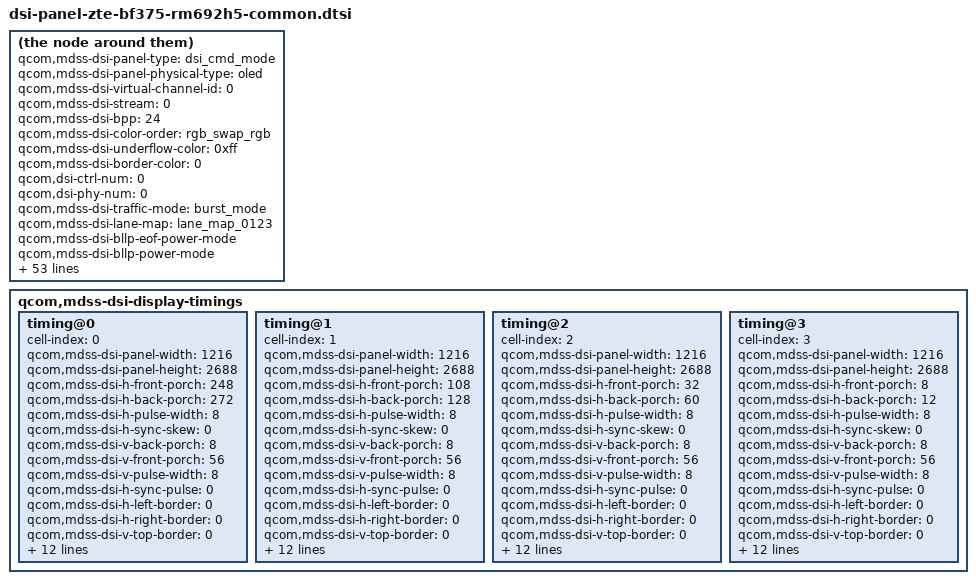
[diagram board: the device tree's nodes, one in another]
qcom,mdss-dsi-panel-type = "dsi_cmd_mode";
qcom,mdss-dsi-panel-physical-type = "oled";
qcom,mdss-dsi-virtual-channel-id = <0>;
qcom,mdss-dsi-stream = <0>;
qcom,mdss-dsi-bpp = <24>;
qcom,mdss-dsi-color-order = "rgb_swap_rgb";
qcom,mdss-dsi-underflow-color = <0xff>;
qcom,mdss-dsi-border-color = <0>;
qcom,dsi-ctrl-num = <0>;
qcom,dsi-phy-num = <0>;
qcom,mdss-dsi-traffic-mode = "burst_mode";
qcom,mdss-dsi-lane-map = "lane_map_0123";
qcom,mdss-dsi-bllp-eof-power-mode;
qcom,mdss-dsi-bllp-power-mode;
qcom,mdss-dsi-lane-0-state;
qcom,mdss-dsi-lane-1-state;
qcom,mdss-dsi-lane-2-state;
qcom,mdss-dsi-lane-3-state;
qcom,mdss-dsi-lp11-init;
qcom,mdss-dsi-tx-eot-append;
/* disp parameter */
qcom,mdss-dsi-dma-trigger = "trigger_sw";
qcom,mdss-dsi-mdp-trigger = "none";
qcom,mdss-dsi-reset-sequence = <1 10>, <0 10>, <1 40>;
qcom,mdss-dsi-te-pin-select = <1>;
qcom,mdss-dsi-te-dcs-command = <1>;
qcom,mdss-dsi-te-check-enable;
qcom,mdss-dsi-te-using-te-pin;
qcom,mdss-dsi-bl-min-level = <2>;
qcom,mdss-dsi-bl-max-level = <8190>; // 7030
qcom,mdss-dsi-panel-hdr-enabled;
qcom,mdss-dsi-panel-hdr-color-primaries = <14500 15500 34015
15980 13030 34670 6950 2565>;
qcom,mdss-dsi-panel-peak-brightness = <6680000>;
qcom,mdss-dsi-panel-blackness-level = <20>;
qcom,mdss-pan-physical-width-dimension = <72>;
qcom,mdss-pan-physical-height-dimension = <158>;
qcom,bl-dcs-cmd-state = "dsi_lp_mode";
qcom,bl-dsc-cmd-state = "dsi_lp_mode";
qcom,mdss-disable-cesta-hw-sleep;

/* feature */
zte,hbm_enabled;
zte,fps_enabled;
zte,aod_enabled;
zte,acl_enabled;
zte,color_space_enabled;
zte,bl_limit_enabled;
zte,te-high-width = <8500>;
zte,bl-normalmax-level = <7030>; // 7030

/* supply */
qcom,panel-supply-entries = <&dsi_panel_pwr_supply>;
qcom,mdss-dsi-bl-pmic-control-type = "bl_ctrl_dcs";
qcom,mdss-brightness-max-level = <8190>;
qcom,mdss-dsi-bl-inverted-dbv;
qcom,platform-reset-gpio = <&tlmm 98 0>;
qcom,ulps-enabled;
qcom,esd-check-enabled;
qcom,mdss-dsi-panel-status-check-mode = "reg_read";
qcom,mdss-dsi-panel-status-command = [
	06 01 00 01 05 00 01 0A
	06 01 00 01 05 00 01 FA
	06 01 00 01 05 00 01 0B];
qcom,mdss-dsi-panel-status-command-state = "dsi_lp_mode";
qcom,mdss-dsi-panel-status-value = <0x9c 0x01 0x00>;
qcom,mdss-dsi-panel-status-read-length = <1 1 1>;
qcom,dsi-select-clocks = "pll_byte_clk0", "pll_dsi_clk0";

/* qcom timing */
qcom,mdss-dsi-display-timings {
	timing@0 {
		cell-index = <0>;
		qcom,mdss-dsi-panel-width = <1216>;
		qcom,mdss-dsi-panel-height = <2688>;
		qcom,mdss-dsi-h-front-porch = <248>;
		qcom,mdss-dsi-h-back-porch = <272>;
		qcom,mdss-dsi-h-pulse-width = <8>;
		qcom,mdss-dsi-h-sync-skew = <0>;
		qcom,mdss-dsi-v-back-porch = <8>;
		qcom,mdss-dsi-v-front-porch = <56>;
		qcom,mdss-dsi-v-pulse-width = <8>;
		qcom,mdss-dsi-h-sync-pulse = <0>;
		qcom,mdss-dsi-h-left-border = <0>;
		qcom,mdss-dsi-h-right-border = <0>;
		qcom,mdss-dsi-v-top-border = <0>;
		qcom,mdss-dsi-v-bottom-border = <0>;
		qcom,mdss-dsi-panel-framerate = <60>;
		qcom,mdss-mdp-transfer-time-us = <6235>;
		/*qcom,mdss-dsi-panel-clockrate = <1060499680>;*/
		/*qcom,mdss-dsi-panel-clockrate = <1059430000>; 60HZ*/
		#include "dsi-panel-zte-bf375-rm692h5-6p8-common.dtsi"
		qcom,mdss-dsi-on-command = [
		/* ESD RECOVER */
		15 01 00 00 00 00 02 FE D4
		15 01 00 00 00 00 02 40 03
		15 01 00 00 00 00 02 FE FD
		15 01 00 00 00 00 02 80 06
		15 01 00 00 00 00 02 83 00
		15 01 00 00 00 00 02 EE 00
		15 01 00 00 00 00 02 EF 00
		15 01 00 00 00 00 02 FE D0
		15 01 00 00 00 00 02 7E 80
		15 01 00 00 00 00 02 FE B6
		15 01 00 00 00 00 02 01 74
		15 01 00 00 00 00 02 FE A1
		15 01 00 00 00 00 02 74 72
		15 01 00 00 00 00 02 C3 C3
		15 01 00 00 00 00 02 C4 FF
		15 01 00 00 00 00 02 C5 7F
		/*10bit 3.75 begin*/
		15 01 00 00 00 00 02 FE 00
		15 01 00 00 00 00 02 FA 01
		15 01 00 00 00 00 02 FE D2
		15 01 00 00 00 00 02 97 08
		15 01 00 00 00 00 02 36 11
		15 01 00 00 00 00 02 39 ab
		15 01 00 00 00 00 02 3A 30
		15 01 00 00 00 00 02 3B 80
		15 01 00 00 00 00 02 3D 0a
		15 01 00 00 00 00 02 3F 80
		15 01 00 00 00 00 02 40 04
		15 01 00 00 00 00 02 41 c0
		15 01 00 00 00 00 02 42 00
		15 01 00 00 00 00 02 43 10
		15 01 00 00 00 00 02 44 02
		15 01 00 00 00 00 02 45 60
		15 01 00 00 00 00 02 46 02
		15 01 00 00 00 00 02 47 60
		15 01 00 00 00 00 02 48 02
		15 01 00 00 00 00 02 49 00
		15 01 00 00 00 00 02 4A 02
		15 01 00 00 00 00 02 4B 31
		15 01 00 00 00 00 02 4D 20
		15 01 00 00 00 00 02 4E 01
		15 01 00 00 00 00 02 4F 68
		15 01 00 00 00 00 02 50 00
		15 01 00 00 00 00 02 51 08
		15 01 00 00 00 00 02 53 0c
		15 01 00 00 00 00 02 54 06
		15 01 00 00 00 00 02 55 67
		15 01 00 00 00 00 02 56 05
		15 01 00 00 00 00 02 58 ad
		15 01 00 00 00 00 02 59 18
		15 01 00 00 00 00 02 5A 00
		15 01 00 00 00 00 02 5B 11
		15 01 00 00 00 00 02 5C 00
		15 01 00 00 00 00 02 5D 07
		15 01 00 00 00 00 02 5E 10
		15 01 00 00 00 00 02 5F 20
		15 01 00 00 00 00 02 60 00
		15 01 00 00 00 00 02 61 06
		15 01 00 00 00 00 02 62 0f
		15 01 00 00 00 00 02 63 0f
		15 01 00 00 00 00 02 64 33
		15 01 00 00 00 00 02 65 0e
		15 01 00 00 00 00 02 66 1c
		15 01 00 00 00 00 02 67 2a
		15 01 00 00 00 00 02 68 38
		15 01 00 00 00 00 02 69 46
		15 01 00 00 00 00 02 6A 54
		15 01 00 00 00 00 02 6B 62
		15 01 00 00 00 00 02 6C 69
		15 01 00 00 00 00 02 6D 70
		15 01 00 00 00 00 02 6E 77
		15 01 00 00 00 00 02 6F 79
		15 01 00 00 00 00 02 70 7b
		15 01 00 00 00 00 02 71 7d
		15 01 00 00 00 00 02 72 7e
		15 01 00 00 00 00 02 73 02
		15 01 00 00 00 00 02 74 02
		15 01 00 00 00 00 02 75 22
		15 01 00 00 00 00 02 76 00
		15 01 00 00 00 00 02 77 2a
		15 01 00 00 00 00 02 78 40
		15 01 00 00 00 00 02 79 2a
		15 01 00 00 00 00 02 7A be
		15 01 00 00 00 00 02 7B 3a
		15 01 00 00 00 00 02 7C fc
		15 01 00 00 00 00 02 7D 3a
		15 01 00 00 00 00 02 7E fa
		15 01 00 00 00 00 02 7F 3a
		15 01 00 00 00 00 02 80 f8
		15 01 00 00 00 00 02 81 3b
		15 01 00 00 00 00 02 82 38
		15 01 00 00 00 00 02 83 3b
		15 01 00 00 00 00 02 84 78
		15 01 00 00 00 00 02 85 3b
		15 01 00 00 00 00 02 86 b6
		15 01 00 00 00 00 02 87 4b
		15 01 00 00 00 00 02 88 f6
		15 01 00 00 00 00 02 89 4c
		15 01 00 00 00 00 02 8A 34
		15 01 00 00 00 00 02 8B 4c
		15 01 00 00 00 00 02 8C 74
		15 01 00 00 00 00 02 8D 5c
		15 01 00 00 00 00 02 8E 74
		15 01 00 00 00 00 02 8F 8c
		15 01 00 00 00 00 02 90 f4
		15 01 00 00 00 00 02 91 00
		15 01 00 00 00 00 02 92 00
		15 01 00 00 00 00 02 93 00
		15 01 00 00 00 00 02 94 00
		15 01 00 00 00 00 02 95 00
		15 01 00 00 00 00 02 96 00
		/*10bit 3.75 end*/

		/*acl function*/
		15 01 00 00 00 00 02 FE 34
		15 01 00 00 00 00 02 82 C0
		15 01 00 00 00 00 02 83 04
		15 01 00 00 00 00 02 00 08
		15 01 00 00 00 00 02 1C 00
		15 01 00 00 00 00 02 1D 10
		15 01 00 00 00 00 02 49 05
		15 01 00 00 00 00 02 1E 00
		15 01 00 00 00 00 02 1F 00
		15 01 00 00 00 00 02 20 00
		15 01 00 00 00 00 02 21 70
		15 01 00 00 00 00 02 22 00
		15 01 00 00 00 00 02 23 F8
		15 01 00 00 00 00 02 24 77
		15 01 00 00 00 00 02 25 F8
		15 01 00 00 00 00 02 26 F8
		15 01 00 00 00 00 02 2F 00
		15 01 00 00 00 00 02 30 00
		15 01 00 00 00 00 02 31 00
		15 01 00 00 00 00 02 32 00
		15 01 00 00 00 00 02 33 00
		15 01 00 00 00 00 02 34 00
		15 01 00 00 00 00 02 35 00
		15 01 00 00 00 00 02 36 C4
		15 01 00 00 00 00 02 37 00
		15 01 00 00 00 00 02 38 87
		15 01 00 00 00 00 02 39 00
		15 01 00 00 00 00 02 3A 4B
		15 01 00 00 00 00 02 3B 00
		15 01 00 00 00 00 02 3D 00
		15 01 00 00 00 00 02 3F 00
		15 01 00 00 00 00 02 40 00
		15 01 00 00 00 00 02 41 00
		15 01 00 00 00 00 02 42 00
		15 01 00 00 00 00 02 54 03
		15 01 00 00 00 00 02 55 77
		15 01 00 00 00 00 02 56 F8
		15 01 00 00 00 00 02 58 F8
		15 01 00 00 00 00 02 59 77
		15 01 00 00 00 00 02 5A F8
		15 01 00 00 00 00 02 5B F8
		15 01 00 00 00 00 02 5C 77
		15 01 00 00 00 00 02 5D F8
		15 01 00 00 00 00 02 5E F8
		15 01 00 00 00 00 02 5F 77
		15 01 00 00 00 00 02 60 F8
		15 01 00 00 00 00 02 61 F8
		15 01 00 00 00 00 02 62 77
		15 01 00 00 00 00 02 63 F8
		15 01 00 00 00 00 02 64 F8
		15 01 00 00 00 00 02 65 77
		15 01 00 00 00 00 02 66 F8
		15 01 00 00 00 00 02 67 F8
		15 01 00 00 00 00 02 77 07
		15 01 00 00 00 00 02 78 F8
/*FDC effect*/
15 01 00 00 00 00 02 FE 00
15 01 00 00 00 00 02 2F 07
15 01 00 00 00 00 02 FE 5A
15 01 00 00 00 00 02 47 f0
15 01 00 00 00 00 02 48 DF
15 01 00 00 00 00 02 49 20
15 01 00 00 00 00 02 4A EE
15 01 00 00 00 00 02 4B EE
15 01 00 00 00 00 02 4C EE
15 01 00 00 00 00 02 4F 10
15 01 00 00 00 00 02 50 16
15 01 00 00 00 00 02 51 00
15 01 00 00 00 00 02 53 08
15 01 00 00 00 00 02 58 00
15 01 00 00 00 00 02 59 00
15 01 00 00 00 00 02 60 00
15 01 00 00 00 00 02 61 00
15 01 00 00 00 00 02 68 F6
15 01 00 00 00 00 02 69 00
15 01 00 00 00 00 02 70 00
15 01 00 00 00 00 02 79 00
15 01 00 00 00 00 02 7A FF
15 01 00 00 00 00 02 7F 01
15 01 00 00 00 00 02 80 00
15 01 00 00 00 00 02 88 FF
15 01 00 00 00 00 02 89 FF
15 01 00 00 00 00 02 8A FF
15 01 00 00 00 00 02 8C 00
15 01 00 00 00 00 02 90 20
15 01 00 00 00 00 02 91 30
15 01 00 00 00 00 02 92 00
15 01 00 00 00 00 02 93 10
15 01 00 00 00 00 02 94 09
15 01 00 00 00 00 02 95 10
15 01 00 00 00 00 02 98 0C
15 01 00 00 00 00 02 99 01
15 01 00 00 00 00 02 9A 02
15 01 00 00 00 00 02 A0 02
15 01 00 00 00 00 02 A2 06
15 01 00 00 00 00 02 A3 04
15 01 00 00 00 00 02 AA 00
15 01 00 00 00 00 02 AB 02
15 01 00 00 00 00 02 B2 06
15 01 00 00 00 00 02 B3 02
15 01 00 00 00 00 02 BA 01
15 01 00 00 00 00 02 BB 03
15 01 00 00 00 00 02 BC 02
15 01 00 00 00 00 02 BD 03
15 01 00 00 00 00 02 C2 03
15 01 00 00 00 00 02 C3 03
15 01 00 00 00 00 02 C4 02
15 01 00 00 00 00 02 C9 02
15 01 00 00 00 00 02 CA 01
15 01 00 00 00 00 02 CB 01
15 01 00 00 00 00 02 DA 40
15 01 00 00 00 00 02 DB 30
15 01 00 00 00 00 02 DC 2A
15 01 00 00 00 00 02 DD 06
15 01 00 00 00 00 02 DE 10
15 01 00 00 00 00 02 DF 06
15 01 00 00 00 00 02 E2 1F
15 01 00 00 00 00 02 E3 20
15 01 00 00 00 00 02 E4 0D
15 01 00 00 00 00 02 EA 12
15 01 00 00 00 00 02 EB 10
15 01 00 00 00 00 02 EC 10
15 01 00 00 00 00 02 F3 04
15 01 00 00 00 00 02 F4 06
15 01 00 00 00 00 02 FE 5B
15 01 00 00 00 00 02 01 10
15 01 00 00 00 00 02 02 06
15 01 00 00 00 00 02 03 02
15 01 00 00 00 00 02 09 03
15 01 00 00 00 00 02 0A 02
15 01 00 00 00 00 02 11 02
15 01 00 00 00 00 02 12 02
15 01 00 00 00 00 02 18 02
15 01 00 00 00 00 02 19 02
15 01 00 00 00 00 02 1B FF
15 01 00 00 00 00 02 21 02
15 01 00 00 00 00 02 22 01
15 01 00 00 00 00 02 23 01
15 01 00 00 00 00 02 24 01
15 01 00 00 00 00 02 25 02
15 01 00 00 00 00 02 29 7f
15 01 00 00 00 00 02 2B FD
15 01 00 00 00 00 02 2D 1F
15 01 00 00 00 00 02 2F 1B
15 01 00 00 00 00 02 30 36
15 01 00 00 00 00 02 33 F9
15 01 00 00 00 00 02 34 00
15 01 00 00 00 00 02 35 FC
15 01 00 00 00 00 02 3B FD
15 01 00 00 00 00 02 3D FF
15 01 00 00 00 00 02 45 FB
15 01 00 00 00 00 02 46 00
15 01 00 00 00 00 02 55 00
15 01 00 00 00 00 02 56 fD
15 01 00 00 00 00 02 5E FF
15 01 00 00 00 00 02 5F 01
15 01 00 00 00 00 02 60 02
15 01 00 00 00 00 02 65 FE
15 01 00 00 00 00 02 66 FF
15 01 00 00 00 00 02 67 01
15 01 00 00 00 00 02 6E 01
15 01 00 00 00 00 02 6F 01
15 01 00 00 00 00 02 70 01
15 01 00 00 00 00 02 71 00
/*avdd 7.9v*/
15 01 00 00 00 00 02 FE 9B
15 01 00 00 00 00 02 0B 4E
		/* init code */
		15 01 00 00 00 00 02 FE 00
		15 01 00 00 00 00 02 C2 08
		15 01 00 00 00 00 02 35 00
		15 01 00 00 00 00 02 53 20
		39 01 00 00 00 00 03 51 00 00
		05 01 00 00 64 00 01 11
		05 01 00 00 14 00 01 29
		];
		qcom,mdss-dsi-on-command-state = "dsi_lp_mode";
		qcom,mdss-dsi-timing-switch-command = [
39 00 00 40 00 00 02 FE 00
39 00 00 40 00 00 02 2F 07
39 00 00 40 00 00 02 FE 5A
39 00 00 40 00 00 02 47 f0
39 00 00 40 00 00 02 48 DF
39 00 00 40 00 00 02 49 20
39 00 00 40 00 00 02 4A EE
39 00 00 40 00 00 02 4B EE
39 00 00 40 00 00 02 4C EE
39 00 00 40 00 00 02 4F 10
39 00 00 40 00 00 02 50 16
39 00 00 40 00 00 02 51 00
39 00 00 40 00 00 02 53 08
39 00 00 40 00 00 02 58 00
39 00 00 40 00 00 02 59 00
39 00 00 40 00 00 02 60 00
39 00 00 40 00 00 02 61 00
39 00 00 40 00 00 02 68 F6
39 00 00 40 00 00 02 69 00
39 00 00 40 00 00 02 70 00
39 00 00 40 00 00 02 79 00
39 00 00 40 00 00 02 7A FF
39 00 00 40 00 00 02 7F 01
39 00 00 40 00 00 02 80 00
39 00 00 40 00 00 02 88 FF
39 00 00 40 00 00 02 89 FF
39 00 00 40 00 00 02 8A FF
39 00 00 40 00 00 02 8C 00
39 00 00 40 00 00 02 90 20
39 00 00 40 00 00 02 91 30
39 00 00 40 00 00 02 92 00
39 00 00 40 00 00 02 93 10
39 00 00 40 00 00 02 94 09
39 00 00 40 00 00 02 95 10
39 00 00 40 00 00 02 98 0C
39 00 00 40 00 00 02 99 01
39 00 00 40 00 00 02 9A 02
39 00 00 40 00 00 02 A0 02
39 00 00 40 00 00 02 A2 06
39 00 00 40 00 00 02 A3 04
39 00 00 40 00 00 02 AA 00
39 00 00 40 00 00 02 AB 02
39 00 00 40 00 00 02 B2 06
39 00 00 40 00 00 02 B3 02
39 00 00 40 00 00 02 BA 01
39 00 00 40 00 00 02 BB 03
39 00 00 40 00 00 02 BC 02
39 00 00 40 00 00 02 BD 03
39 00 00 40 00 00 02 C2 03
39 00 00 40 00 00 02 C3 03
39 00 00 40 00 00 02 C4 02
39 00 00 40 00 00 02 C9 02
39 00 00 40 00 00 02 CA 01
39 00 00 40 00 00 02 CB 01
39 00 00 40 00 00 02 DA 40
39 00 00 40 00 00 02 DB 30
39 00 00 40 00 00 02 DC 2A
39 00 00 40 00 00 02 DD 06
39 00 00 40 00 00 02 DE 10
39 00 00 40 00 00 02 DF 06
39 00 00 40 00 00 02 E2 1F
39 00 00 40 00 00 02 E3 20
39 00 00 40 00 00 02 E4 0D
39 00 00 40 00 00 02 EA 12
39 00 00 40 00 00 02 EB 10
39 00 00 40 00 00 02 EC 10
39 00 00 40 00 00 02 F3 04
39 00 00 40 00 00 02 F4 06
39 00 00 40 00 00 02 FE 5B
39 00 00 40 00 00 02 01 10
39 00 00 40 00 00 02 02 06
39 00 00 40 00 00 02 03 02
39 00 00 40 00 00 02 09 03
39 00 00 40 00 00 02 0A 02
39 00 00 40 00 00 02 11 02
39 00 00 40 00 00 02 12 02
39 00 00 40 00 00 02 18 02
39 00 00 40 00 00 02 19 02
39 00 00 40 00 00 02 1B FF
39 00 00 40 00 00 02 21 02
39 00 00 40 00 00 02 22 01
39 00 00 40 00 00 02 23 01
39 00 00 40 00 00 02 24 01
39 00 00 40 00 00 02 25 02
39 00 00 40 00 00 02 29 7f
39 00 00 40 00 00 02 2B FD
39 00 00 40 00 00 02 2D 1F
39 00 00 40 00 00 02 2F 1B
39 00 00 40 00 00 02 30 36
39 00 00 40 00 00 02 33 F9
39 00 00 40 00 00 02 34 00
39 00 00 40 00 00 02 35 FC
39 00 00 40 00 00 02 3B FD
39 00 00 40 00 00 02 3D FF
39 00 00 40 00 00 02 45 FB
39 00 00 40 00 00 02 46 00
39 00 00 40 00 00 02 55 00
39 00 00 40 00 00 02 56 fD
39 00 00 40 00 00 02 5E FF
39 00 00 40 00 00 02 5F 01
39 00 00 40 00 00 02 60 02
39 00 00 40 00 00 02 65 FE
39 00 00 40 00 00 02 66 FF
39 00 00 40 00 00 02 67 01
39 00 00 40 00 00 02 6E 01
39 00 00 40 00 00 02 6F 01
39 00 00 40 00 00 02 70 01
39 00 00 40 00 00 02 71 00
		39 00 00 00 00 00 02 FE 00
		];
		qcom,mdss-dsi-timing-switch-command-state =
		"dsi_lp_mode";
/* DPHY regular margins */
qcom,mdss-dsi-panel-phy-timings = [00 23 09 09 1A 24
	09 09 09 02 04 00 1D 0E];
	};
	timing@1{
		cell-index = <1>;
		qcom,mdss-dsi-panel-width = <1216>;
		qcom,mdss-dsi-panel-height = <2688>;
		qcom,mdss-dsi-h-front-porch = <108>;
		qcom,mdss-dsi-h-back-porch = <128>;
		qcom,mdss-dsi-h-pulse-width = <8>;
		qcom,mdss-dsi-h-sync-skew = <0>;
		qcom,mdss-dsi-v-back-porch = <8>;
		qcom,mdss-dsi-v-front-porch = <56>;
		qcom,mdss-dsi-v-pulse-width = <8>;
		qcom,mdss-dsi-h-sync-pulse = <0>;
		qcom,mdss-dsi-h-left-border = <0>;
		qcom,mdss-dsi-h-right-border = <0>;
		qcom,mdss-dsi-v-top-border = <0>;
		qcom,mdss-dsi-v-bottom-border = <0>;
		qcom,mdss-dsi-panel-framerate = <90>;
		qcom,mdss-mdp-transfer-time-us = <6235>;
		/*qcom,mdss-dsi-panel-clockrate = <1060531504>;*/
		/*qcom,mdss-dsi-panel-clockrate = <1060050000>; 90HZ*/
		#include "dsi-panel-zte-bf375-rm692h5-6p8-common.dtsi"

		qcom,mdss-dsi-on-command = [
		/* ESD RECOVER */
		15 01 00 00 00 00 02 FE D4
		15 01 00 00 00 00 02 40 03
		15 01 00 00 00 00 02 FE FD
		15 01 00 00 00 00 02 80 06
		15 01 00 00 00 00 02 83 00
		15 01 00 00 00 00 02 EE 00
		15 01 00 00 00 00 02 EF 00
		15 01 00 00 00 00 02 FE D0
		15 01 00 00 00 00 02 7E 80
		15 01 00 00 00 00 02 FE B6
		15 01 00 00 00 00 02 01 74
		15 01 00 00 00 00 02 FE A1
		15 01 00 00 00 00 02 74 72
		15 01 00 00 00 00 02 C3 C3
		15 01 00 00 00 00 02 C4 FF
		15 01 00 00 00 00 02 C5 7F
		/*10bit 3.75 begin*/
		15 01 00 00 00 00 02 FE 00
		15 01 00 00 00 00 02 FA 01
		15 01 00 00 00 00 02 FE D2
		15 01 00 00 00 00 02 97 08
		15 01 00 00 00 00 02 36 11
		15 01 00 00 00 00 02 39 ab
		15 01 00 00 00 00 02 3A 30
		15 01 00 00 00 00 02 3B 80
		15 01 00 00 00 00 02 3D 0a
		15 01 00 00 00 00 02 3F 80
		15 01 00 00 00 00 02 40 04
		15 01 00 00 00 00 02 41 c0
		15 01 00 00 00 00 02 42 00
		15 01 00 00 00 00 02 43 10
		15 01 00 00 00 00 02 44 02
		15 01 00 00 00 00 02 45 60
		15 01 00 00 00 00 02 46 02
		15 01 00 00 00 00 02 47 60
		15 01 00 00 00 00 02 48 02
		15 01 00 00 00 00 02 49 00
		15 01 00 00 00 00 02 4A 02
		15 01 00 00 00 00 02 4B 31
		15 01 00 00 00 00 02 4D 20
		15 01 00 00 00 00 02 4E 01
		15 01 00 00 00 00 02 4F 68
		15 01 00 00 00 00 02 50 00
		15 01 00 00 00 00 02 51 08
		15 01 00 00 00 00 02 53 0c
		15 01 00 00 00 00 02 54 06
		15 01 00 00 00 00 02 55 67
		15 01 00 00 00 00 02 56 05
		15 01 00 00 00 00 02 58 ad
		15 01 00 00 00 00 02 59 18
		15 01 00 00 00 00 02 5A 00
		15 01 00 00 00 00 02 5B 11
		15 01 00 00 00 00 02 5C 00
		15 01 00 00 00 00 02 5D 07
		15 01 00 00 00 00 02 5E 10
		15 01 00 00 00 00 02 5F 20
		15 01 00 00 00 00 02 60 00
		15 01 00 00 00 00 02 61 06
		15 01 00 00 00 00 02 62 0f
		15 01 00 00 00 00 02 63 0f
		15 01 00 00 00 00 02 64 33
		15 01 00 00 00 00 02 65 0e
		15 01 00 00 00 00 02 66 1c
		15 01 00 00 00 00 02 67 2a
		15 01 00 00 00 00 02 68 38
		15 01 00 00 00 00 02 69 46
		15 01 00 00 00 00 02 6A 54
		15 01 00 00 00 00 02 6B 62
		15 01 00 00 00 00 02 6C 69
		15 01 00 00 00 00 02 6D 70
		15 01 00 00 00 00 02 6E 77
		15 01 00 00 00 00 02 6F 79
		15 01 00 00 00 00 02 70 7b
		15 01 00 00 00 00 02 71 7d
		15 01 00 00 00 00 02 72 7e
		15 01 00 00 00 00 02 73 02
		15 01 00 00 00 00 02 74 02
		15 01 00 00 00 00 02 75 22
		15 01 00 00 00 00 02 76 00
		15 01 00 00 00 00 02 77 2a
		15 01 00 00 00 00 02 78 40
		15 01 00 00 00 00 02 79 2a
		15 01 00 00 00 00 02 7A be
		15 01 00 00 00 00 02 7B 3a
		15 01 00 00 00 00 02 7C fc
		15 01 00 00 00 00 02 7D 3a
		15 01 00 00 00 00 02 7E fa
		15 01 00 00 00 00 02 7F 3a
		15 01 00 00 00 00 02 80 f8
		15 01 00 00 00 00 02 81 3b
		15 01 00 00 00 00 02 82 38
		15 01 00 00 00 00 02 83 3b
		15 01 00 00 00 00 02 84 78
		15 01 00 00 00 00 02 85 3b
		15 01 00 00 00 00 02 86 b6
		15 01 00 00 00 00 02 87 4b
		15 01 00 00 00 00 02 88 f6
		15 01 00 00 00 00 02 89 4c
		15 01 00 00 00 00 02 8A 34
		15 01 00 00 00 00 02 8B 4c
		15 01 00 00 00 00 02 8C 74
		15 01 00 00 00 00 02 8D 5c
		15 01 00 00 00 00 02 8E 74
		15 01 00 00 00 00 02 8F 8c
		15 01 00 00 00 00 02 90 f4
		15 01 00 00 00 00 02 91 00
		15 01 00 00 00 00 02 92 00
		15 01 00 00 00 00 02 93 00
		15 01 00 00 00 00 02 94 00
		15 01 00 00 00 00 02 95 00
		15 01 00 00 00 00 02 96 00
		/*10bit 3.75 end*/
		/*acl function*/
		15 01 00 00 00 00 02 FE 34
		15 01 00 00 00 00 02 82 C0
		15 01 00 00 00 00 02 83 04
		15 01 00 00 00 00 02 00 08
		15 01 00 00 00 00 02 1C 00
		15 01 00 00 00 00 02 1D 10
		15 01 00 00 00 00 02 49 05
		15 01 00 00 00 00 02 1E 00
		15 01 00 00 00 00 02 1F 00
		15 01 00 00 00 00 02 20 00
		15 01 00 00 00 00 02 21 70
		15 01 00 00 00 00 02 22 00
		15 01 00 00 00 00 02 23 F8
		15 01 00 00 00 00 02 24 77
		15 01 00 00 00 00 02 25 F8
		15 01 00 00 00 00 02 26 F8
		15 01 00 00 00 00 02 2F 00
		15 01 00 00 00 00 02 30 00
		15 01 00 00 00 00 02 31 00
		15 01 00 00 00 00 02 32 00
		15 01 00 00 00 00 02 33 00
		15 01 00 00 00 00 02 34 00
		15 01 00 00 00 00 02 35 00
		15 01 00 00 00 00 02 36 C4
		15 01 00 00 00 00 02 37 00
		15 01 00 00 00 00 02 38 87
		15 01 00 00 00 00 02 39 00
		15 01 00 00 00 00 02 3A 4B
		15 01 00 00 00 00 02 3B 00
		15 01 00 00 00 00 02 3D 00
		15 01 00 00 00 00 02 3F 00
		15 01 00 00 00 00 02 40 00
		15 01 00 00 00 00 02 41 00
		15 01 00 00 00 00 02 42 00
		15 01 00 00 00 00 02 54 03
		15 01 00 00 00 00 02 55 77
		15 01 00 00 00 00 02 56 F8
		15 01 00 00 00 00 02 58 F8
		15 01 00 00 00 00 02 59 77
		15 01 00 00 00 00 02 5A F8
		15 01 00 00 00 00 02 5B F8
		15 01 00 00 00 00 02 5C 77
		15 01 00 00 00 00 02 5D F8
		15 01 00 00 00 00 02 5E F8
		15 01 00 00 00 00 02 5F 77
		15 01 00 00 00 00 02 60 F8
		15 01 00 00 00 00 02 61 F8
		15 01 00 00 00 00 02 62 77
		15 01 00 00 00 00 02 63 F8
		15 01 00 00 00 00 02 64 F8
		15 01 00 00 00 00 02 65 77
		15 01 00 00 00 00 02 66 F8
		15 01 00 00 00 00 02 67 F8
		15 01 00 00 00 00 02 77 07
		15 01 00 00 00 00 02 78 F8
/*FDC effect*/
15 01 00 00 00 00 02 FE 00
15 01 00 00 00 00 02 2F 06
15 01 00 00 00 00 02 FE 5A
15 01 00 00 00 00 02 47 FF
15 01 00 00 00 00 02 48 DF
15 01 00 00 00 00 02 49 10
15 01 00 00 00 00 02 4A FC
15 01 00 00 00 00 02 4B FF
15 01 00 00 00 00 02 4F 10
15 01 00 00 00 00 02 50 FF
15 01 00 00 00 00 02 51 FE
15 01 00 00 00 00 02 53 08
15 01 00 00 00 00 02 58 05
15 01 00 00 00 00 02 60 FD
15 01 00 00 00 00 02 61 00
15 01 00 00 00 00 02 68 FD
15 01 00 00 00 00 02 69 00
15 01 00 00 00 00 02 70 01
15 01 00 00 00 00 02 79 00
15 01 00 00 00 00 02 7A FF
15 01 00 00 00 00 02 7F 01
15 01 00 00 00 00 02 80 FE
15 01 00 00 00 00 02 88 FF
15 01 00 00 00 00 02 89 FF
15 01 00 00 00 00 02 8A FF
15 01 00 00 00 00 02 8C 00
15 01 00 00 00 00 02 90 00
15 01 00 00 00 00 02 91 40
15 01 00 00 00 00 02 92 0B
15 01 00 00 00 00 02 93 14
15 01 00 00 00 00 02 94 0F
15 01 00 00 00 00 02 95 03
15 01 00 00 00 00 02 98 0C
15 01 00 00 00 00 02 99 08
15 01 00 00 00 00 02 9A 08
15 01 00 00 00 00 02 A0 0B
15 01 00 00 00 00 02 A2 06
15 01 00 00 00 00 02 A3 06
15 01 00 00 00 00 02 AA 07
15 01 00 00 00 00 02 AB 02
15 01 00 00 00 00 02 B2 07
15 01 00 00 00 00 02 B3 05
15 01 00 00 00 00 02 BA 04
15 01 00 00 00 00 02 BB 03
15 01 00 00 00 00 02 BC 02
15 01 00 00 00 00 02 BD 03
15 01 00 00 00 00 02 C2 03
15 01 00 00 00 00 02 C3 03
15 01 00 00 00 00 02 C4 02
15 01 00 00 00 00 02 C9 02
15 01 00 00 00 00 02 CA 02
15 01 00 00 00 00 02 CB 01
15 01 00 00 00 00 02 DA 70
15 01 00 00 00 00 02 DB 30
15 01 00 00 00 00 02 DC 30
15 01 00 00 00 00 02 DD 1C
15 01 00 00 00 00 02 DE 02
15 01 00 00 00 00 02 DF 1B
15 01 00 00 00 00 02 E2 1F
15 01 00 00 00 00 02 E3 20
15 01 00 00 00 00 02 E4 18
15 01 00 00 00 00 02 EA 18
15 01 00 00 00 00 02 EB 10
15 01 00 00 00 00 02 EC 14
15 01 00 00 00 00 02 F3 0C
15 01 00 00 00 00 02 F4 06
15 01 00 00 00 00 02 FE 5B
15 01 00 00 00 00 02 01 10
15 01 00 00 00 00 02 02 08
15 01 00 00 00 00 02 03 04
15 01 00 00 00 00 02 09 06
15 01 00 00 00 00 02 0A 05
15 01 00 00 00 00 02 11 02
15 01 00 00 00 00 02 12 02
15 01 00 00 00 00 02 18 02
15 01 00 00 00 00 02 19 07
15 01 00 00 00 00 02 1B FF
15 01 00 00 00 00 02 21 02
15 01 00 00 00 00 02 22 01
15 01 00 00 00 00 02 23 01
15 01 00 00 00 00 02 24 01
15 01 00 00 00 00 02 25 02
15 01 00 00 00 00 02 29 10
15 01 00 00 00 00 02 2B 20
15 01 00 00 00 00 02 2D 1C
15 01 00 00 00 00 02 2F 10
15 01 00 00 00 00 02 30 22
15 01 00 00 00 00 02 33 F9
15 01 00 00 00 00 02 34 FF
15 01 00 00 00 00 02 35 00
15 01 00 00 00 00 02 3B F9
15 01 00 00 00 00 02 3D 00
15 01 00 00 00 00 02 45 FE
15 01 00 00 00 00 02 46 00
15 01 00 00 00 00 02 55 FF
15 01 00 00 00 00 02 56 fD
15 01 00 00 00 00 02 5E FF
15 01 00 00 00 00 02 5F 01
15 01 00 00 00 00 02 60 02
15 01 00 00 00 00 02 65 FE
15 01 00 00 00 00 02 66 01
15 01 00 00 00 00 02 67 FC
15 01 00 00 00 00 02 6E 01
15 01 00 00 00 00 02 6F 01
15 01 00 00 00 00 02 70 01
15 01 00 00 00 00 02 71 00
/*avdd 7.9v*/
15 01 00 00 00 00 02 FE 9B
15 01 00 00 00 00 02 0B 4E
		/* init code */
		15 01 00 00 00 00 02 FE 00
		15 01 00 00 00 00 02 C2 08
		15 01 00 00 00 00 02 35 00
		15 01 00 00 00 00 02 53 20
		39 01 00 00 00 00 03 51 00 00
		05 01 00 00 64 00 01 11
		05 01 00 00 14 00 01 29
		];
		qcom,mdss-dsi-on-command-state = "dsi_lp_mode";
		qcom,mdss-dsi-timing-switch-command = [
39 00 00 40 00 00 02 FE 00
39 00 00 40 00 00 02 2F 06
39 00 00 40 00 00 02 FE 5A
39 00 00 40 00 00 02 47 FF
39 00 00 40 00 00 02 48 DF
39 00 00 40 00 00 02 49 10
39 00 00 40 00 00 02 4A FC
39 00 00 40 00 00 02 4B FF
39 00 00 40 00 00 02 4F 10
39 00 00 40 00 00 02 50 FF
39 00 00 40 00 00 02 51 FE
39 00 00 40 00 00 02 53 08
39 00 00 40 00 00 02 58 05
39 00 00 40 00 00 02 60 FD
39 00 00 40 00 00 02 61 00
39 00 00 40 00 00 02 68 FD
39 00 00 40 00 00 02 69 00
39 00 00 40 00 00 02 70 01
39 00 00 40 00 00 02 79 00
39 00 00 40 00 00 02 7A FF
39 00 00 40 00 00 02 7F 01
39 00 00 40 00 00 02 80 FE
39 00 00 40 00 00 02 88 FF
39 00 00 40 00 00 02 89 FF
39 00 00 40 00 00 02 8A FF
39 00 00 40 00 00 02 8C 00
39 00 00 40 00 00 02 90 00
39 00 00 40 00 00 02 91 40
39 00 00 40 00 00 02 92 0B
39 00 00 40 00 00 02 93 14
39 00 00 40 00 00 02 94 0F
39 00 00 40 00 00 02 95 03
39 00 00 40 00 00 02 98 0C
39 00 00 40 00 00 02 99 08
39 00 00 40 00 00 02 9A 08
39 00 00 40 00 00 02 A0 0B
39 00 00 40 00 00 02 A2 06
39 00 00 40 00 00 02 A3 06
39 00 00 40 00 00 02 AA 07
39 00 00 40 00 00 02 AB 02
39 00 00 40 00 00 02 B2 07
39 00 00 40 00 00 02 B3 05
39 00 00 40 00 00 02 BA 04
39 00 00 40 00 00 02 BB 03
39 00 00 40 00 00 02 BC 02
39 00 00 40 00 00 02 BD 03
39 00 00 40 00 00 02 C2 03
39 00 00 40 00 00 02 C3 03
39 00 00 40 00 00 02 C4 02
39 00 00 40 00 00 02 C9 02
39 00 00 40 00 00 02 CA 02
39 00 00 40 00 00 02 CB 01
39 00 00 40 00 00 02 DA 70
39 00 00 40 00 00 02 DB 30
39 00 00 40 00 00 02 DC 30
39 00 00 40 00 00 02 DD 1C
39 00 00 40 00 00 02 DE 02
39 00 00 40 00 00 02 DF 1B
39 00 00 40 00 00 02 E2 1F
39 00 00 40 00 00 02 E3 20
39 00 00 40 00 00 02 E4 18
39 00 00 40 00 00 02 EA 18
39 00 00 40 00 00 02 EB 10
39 00 00 40 00 00 02 EC 14
39 00 00 40 00 00 02 F3 0C
39 00 00 40 00 00 02 F4 06
39 00 00 40 00 00 02 FE 5B
39 00 00 40 00 00 02 01 10
39 00 00 40 00 00 02 02 08
39 00 00 40 00 00 02 03 04
39 00 00 40 00 00 02 09 06
39 00 00 40 00 00 02 0A 05
39 00 00 40 00 00 02 11 02
39 00 00 40 00 00 02 12 02
39 00 00 40 00 00 02 18 02
39 00 00 40 00 00 02 19 07
39 00 00 40 00 00 02 1B FF
39 00 00 40 00 00 02 21 02
39 00 00 40 00 00 02 22 01
39 00 00 40 00 00 02 23 01
39 00 00 40 00 00 02 24 01
39 00 00 40 00 00 02 25 02
39 00 00 40 00 00 02 29 10
39 00 00 40 00 00 02 2B 20
39 00 00 40 00 00 02 2D 1C
39 00 00 40 00 00 02 2F 10
39 00 00 40 00 00 02 30 22
39 00 00 40 00 00 02 33 F9
39 00 00 40 00 00 02 34 FF
39 00 00 40 00 00 02 35 00
39 00 00 40 00 00 02 3B F9
39 00 00 40 00 00 02 3D 00
39 00 00 40 00 00 02 45 FE
39 00 00 40 00 00 02 46 00
39 00 00 40 00 00 02 55 FF
39 00 00 40 00 00 02 56 fD
39 00 00 40 00 00 02 5E FF
39 00 00 40 00 00 02 5F 01
39 00 00 40 00 00 02 60 02
39 00 00 40 00 00 02 65 FE
39 00 00 40 00 00 02 66 01
39 00 00 40 00 00 02 67 FC
39 00 00 40 00 00 02 6E 01
39 00 00 40 00 00 02 6F 01
39 00 00 40 00 00 02 70 01
39 00 00 40 00 00 02 71 00
		39 00 00 00 00 00 02 FE 00
		];
		qcom,mdss-dsi-timing-switch-command-state =
		"dsi_lp_mode";
/* DPHY regular margins */
qcom,mdss-dsi-panel-phy-timings = [00 23 09 09 1A 24
	09 09 09 02 04 00 1D 0E];
	};
	timing@2{
		cell-index = <2>;
		qcom,mdss-dsi-panel-width = <1216>;
		qcom,mdss-dsi-panel-height = <2688>;
		qcom,mdss-dsi-h-front-porch = <32>;
		qcom,mdss-dsi-h-back-porch = <60>;
		qcom,mdss-dsi-h-pulse-width = <8>;
		qcom,mdss-dsi-h-sync-skew = <0>;
		qcom,mdss-dsi-v-back-porch = <8>;
		qcom,mdss-dsi-v-front-porch = <56>;
		qcom,mdss-dsi-v-pulse-width = <8>;
		qcom,mdss-dsi-h-sync-pulse = <0>;
		qcom,mdss-dsi-h-left-border = <0>;
		qcom,mdss-dsi-h-right-border = <0>;
		qcom,mdss-dsi-v-top-border = <0>;
		qcom,mdss-dsi-v-bottom-border = <0>;
		qcom,mdss-dsi-panel-framerate = <120>;
		qcom,mdss-mdp-transfer-time-us = <6235>;
		/*qcom,mdss-dsi-panel-clockrate = <1060499680>;*/
		/*qcom,mdss-dsi-panel-clockrate = <1055700000>; 120HZ*/
		#include "dsi-panel-zte-bf375-rm692h5-6p8-common.dtsi"

		qcom,mdss-dsi-on-command = [
		/* ESD RECOVER */
		15 01 00 00 00 00 02 FE D4
		15 01 00 00 00 00 02 40 03
		15 01 00 00 00 00 02 FE FD
		15 01 00 00 00 00 02 80 06
		15 01 00 00 00 00 02 83 00
		15 01 00 00 00 00 02 EE 00
		15 01 00 00 00 00 02 EF 00
		15 01 00 00 00 00 02 FE D0
		15 01 00 00 00 00 02 7E 80
		15 01 00 00 00 00 02 FE B6
		15 01 00 00 00 00 02 01 74
		15 01 00 00 00 00 02 FE A1
		15 01 00 00 00 00 02 74 72
		15 01 00 00 00 00 02 C3 C3
		15 01 00 00 00 00 02 C4 FF
		15 01 00 00 00 00 02 C5 7F
		/*10bit 3.75 begin*/
		15 01 00 00 00 00 02 FE 00
		15 01 00 00 00 00 02 FA 01
		15 01 00 00 00 00 02 FE D2
		15 01 00 00 00 00 02 97 08
		15 01 00 00 00 00 02 36 11
		15 01 00 00 00 00 02 39 ab
		15 01 00 00 00 00 02 3A 30
		15 01 00 00 00 00 02 3B 80
		15 01 00 00 00 00 02 3D 0a
		15 01 00 00 00 00 02 3F 80
		15 01 00 00 00 00 02 40 04
		15 01 00 00 00 00 02 41 c0
		15 01 00 00 00 00 02 42 00
		15 01 00 00 00 00 02 43 10
		15 01 00 00 00 00 02 44 02
		15 01 00 00 00 00 02 45 60
		15 01 00 00 00 00 02 46 02
		15 01 00 00 00 00 02 47 60
		15 01 00 00 00 00 02 48 02
		15 01 00 00 00 00 02 49 00
		15 01 00 00 00 00 02 4A 02
		15 01 00 00 00 00 02 4B 31
		15 01 00 00 00 00 02 4D 20
		15 01 00 00 00 00 02 4E 01
		15 01 00 00 00 00 02 4F 68
		15 01 00 00 00 00 02 50 00
		15 01 00 00 00 00 02 51 08
		15 01 00 00 00 00 02 53 0c
		15 01 00 00 00 00 02 54 06
		15 01 00 00 00 00 02 55 67
		15 01 00 00 00 00 02 56 05
		15 01 00 00 00 00 02 58 ad
		15 01 00 00 00 00 02 59 18
		15 01 00 00 00 00 02 5A 00
		15 01 00 00 00 00 02 5B 11
		15 01 00 00 00 00 02 5C 00
		15 01 00 00 00 00 02 5D 07
		15 01 00 00 00 00 02 5E 10
		15 01 00 00 00 00 02 5F 20
		15 01 00 00 00 00 02 60 00
		15 01 00 00 00 00 02 61 06
		15 01 00 00 00 00 02 62 0f
		15 01 00 00 00 00 02 63 0f
		15 01 00 00 00 00 02 64 33
		15 01 00 00 00 00 02 65 0e
		15 01 00 00 00 00 02 66 1c
		15 01 00 00 00 00 02 67 2a
		15 01 00 00 00 00 02 68 38
		15 01 00 00 00 00 02 69 46
		15 01 00 00 00 00 02 6A 54
		15 01 00 00 00 00 02 6B 62
		15 01 00 00 00 00 02 6C 69
		15 01 00 00 00 00 02 6D 70
		15 01 00 00 00 00 02 6E 77
		15 01 00 00 00 00 02 6F 79
		15 01 00 00 00 00 02 70 7b
		15 01 00 00 00 00 02 71 7d
		15 01 00 00 00 00 02 72 7e
		15 01 00 00 00 00 02 73 02
		15 01 00 00 00 00 02 74 02
		15 01 00 00 00 00 02 75 22
		15 01 00 00 00 00 02 76 00
		15 01 00 00 00 00 02 77 2a
		15 01 00 00 00 00 02 78 40
		15 01 00 00 00 00 02 79 2a
		15 01 00 00 00 00 02 7A be
		15 01 00 00 00 00 02 7B 3a
		15 01 00 00 00 00 02 7C fc
		15 01 00 00 00 00 02 7D 3a
		15 01 00 00 00 00 02 7E fa
		15 01 00 00 00 00 02 7F 3a
		15 01 00 00 00 00 02 80 f8
		15 01 00 00 00 00 02 81 3b
		15 01 00 00 00 00 02 82 38
		15 01 00 00 00 00 02 83 3b
		15 01 00 00 00 00 02 84 78
		15 01 00 00 00 00 02 85 3b
		15 01 00 00 00 00 02 86 b6
		15 01 00 00 00 00 02 87 4b
		15 01 00 00 00 00 02 88 f6
		15 01 00 00 00 00 02 89 4c
		15 01 00 00 00 00 02 8A 34
		15 01 00 00 00 00 02 8B 4c
		15 01 00 00 00 00 02 8C 74
		15 01 00 00 00 00 02 8D 5c
		15 01 00 00 00 00 02 8E 74
		15 01 00 00 00 00 02 8F 8c
		15 01 00 00 00 00 02 90 f4
		15 01 00 00 00 00 02 91 00
		15 01 00 00 00 00 02 92 00
		15 01 00 00 00 00 02 93 00
		15 01 00 00 00 00 02 94 00
		15 01 00 00 00 00 02 95 00
		15 01 00 00 00 00 02 96 00
		/*10bit 3.75 end*/
		/*acl function*/
		15 01 00 00 00 00 02 FE 34
		15 01 00 00 00 00 02 82 C0
		15 01 00 00 00 00 02 83 04
		15 01 00 00 00 00 02 00 08
		15 01 00 00 00 00 02 1C 00
		15 01 00 00 00 00 02 1D 10
		15 01 00 00 00 00 02 49 05
		15 01 00 00 00 00 02 1E 00
		15 01 00 00 00 00 02 1F 00
		15 01 00 00 00 00 02 20 00
		15 01 00 00 00 00 02 21 70
		15 01 00 00 00 00 02 22 00
		15 01 00 00 00 00 02 23 F8
		15 01 00 00 00 00 02 24 77
		15 01 00 00 00 00 02 25 F8
		15 01 00 00 00 00 02 26 F8
		15 01 00 00 00 00 02 2F 00
		15 01 00 00 00 00 02 30 00
		15 01 00 00 00 00 02 31 00
		15 01 00 00 00 00 02 32 00
		15 01 00 00 00 00 02 33 00
		15 01 00 00 00 00 02 34 00
		15 01 00 00 00 00 02 35 00
		15 01 00 00 00 00 02 36 C4
		15 01 00 00 00 00 02 37 00
		15 01 00 00 00 00 02 38 87
		15 01 00 00 00 00 02 39 00
		15 01 00 00 00 00 02 3A 4B
		15 01 00 00 00 00 02 3B 00
		15 01 00 00 00 00 02 3D 00
		15 01 00 00 00 00 02 3F 00
		15 01 00 00 00 00 02 40 00
		15 01 00 00 00 00 02 41 00
		15 01 00 00 00 00 02 42 00
		15 01 00 00 00 00 02 54 03
		15 01 00 00 00 00 02 55 77
		15 01 00 00 00 00 02 56 F8
		15 01 00 00 00 00 02 58 F8
		15 01 00 00 00 00 02 59 77
		15 01 00 00 00 00 02 5A F8
		15 01 00 00 00 00 02 5B F8
		15 01 00 00 00 00 02 5C 77
		15 01 00 00 00 00 02 5D F8
		15 01 00 00 00 00 02 5E F8
		15 01 00 00 00 00 02 5F 77
		15 01 00 00 00 00 02 60 F8
		15 01 00 00 00 00 02 61 F8
		15 01 00 00 00 00 02 62 77
		15 01 00 00 00 00 02 63 F8
		15 01 00 00 00 00 02 64 F8
		15 01 00 00 00 00 02 65 77
		15 01 00 00 00 00 02 66 F8
		15 01 00 00 00 00 02 67 F8
		15 01 00 00 00 00 02 77 07
		15 01 00 00 00 00 02 78 F8
/*FDC effect*/
15 01 00 00 00 00 02 FE 00
15 01 00 00 00 00 02 2F 05
15 01 00 00 00 00 02 FE 5A
15 01 00 00 00 00 02 47 FF
15 01 00 00 00 00 02 48 F0
15 01 00 00 00 00 02 49 3A
15 01 00 00 00 00 02 4A 00
15 01 00 00 00 00 02 4B 10
15 01 00 00 00 00 02 4C FC
15 01 00 00 00 00 02 4F 22
15 01 00 00 00 00 02 50 30
15 01 00 00 00 00 02 51 00
15 01 00 00 00 00 02 53 08
15 01 00 00 00 00 02 58 05
15 01 00 00 00 00 02 59 00
15 01 00 00 00 00 02 60 00
15 01 00 00 00 00 02 61 00
15 01 00 00 00 00 02 68 F6
15 01 00 00 00 00 02 69 00
15 01 00 00 00 00 02 70 00
15 01 00 00 00 00 02 79 01
15 01 00 00 00 00 02 7A 00
15 01 00 00 00 00 02 7F 02
15 01 00 00 00 00 02 80 01
15 01 00 00 00 00 02 88 00
15 01 00 00 00 00 02 89 00
15 01 00 00 00 00 02 8A 00
15 01 00 00 00 00 02 8C FF
15 01 00 00 00 00 02 90 00
15 01 00 00 00 00 02 91 30
15 01 00 00 00 00 02 92 10
15 01 00 00 00 00 02 93 10
15 01 00 00 00 00 02 94 09
15 01 00 00 00 00 02 95 1D
15 01 00 00 00 00 02 98 0E
15 01 00 00 00 00 02 99 16
15 01 00 00 00 00 02 9A 10
15 01 00 00 00 00 02 A0 10
15 01 00 00 00 00 02 A2 09
15 01 00 00 00 00 02 A3 06
15 01 00 00 00 00 02 AA 00
15 01 00 00 00 00 02 AB 00
15 01 00 00 00 00 02 B2 07
15 01 00 00 00 00 02 B3 03
15 01 00 00 00 00 02 BA 01
15 01 00 00 00 00 02 BB 01
15 01 00 00 00 00 02 BC 02
15 01 00 00 00 00 02 BD 00
15 01 00 00 00 00 02 C2 04
15 01 00 00 00 00 02 C3 04
15 01 00 00 00 00 02 C4 02
15 01 00 00 00 00 02 C9 05
15 01 00 00 00 00 02 CA 01
15 01 00 00 00 00 02 CB 01
15 01 00 00 00 00 02 DA 70
15 01 00 00 00 00 02 DB 4C
15 01 00 00 00 00 02 DC 3F
15 01 00 00 00 00 02 DD 15
15 01 00 00 00 00 02 DE 12
15 01 00 00 00 00 02 DF 1B
15 01 00 00 00 00 02 E2 23
15 01 00 00 00 00 02 E3 3C
15 01 00 00 00 00 02 E4 28
15 01 00 00 00 00 02 EA 1F
15 01 00 00 00 00 02 EB 1A
15 01 00 00 00 00 02 EC 14
15 01 00 00 00 00 02 F3 10
15 01 00 00 00 00 02 F4 08
15 01 00 00 00 00 02 FE 5B
15 01 00 00 00 00 02 01 12
15 01 00 00 00 00 02 02 0B
15 01 00 00 00 00 02 03 04
15 01 00 00 00 00 02 09 08
15 01 00 00 00 00 02 0A 05
15 01 00 00 00 00 02 11 08
15 01 00 00 00 00 02 12 05
15 01 00 00 00 00 02 18 0A
15 01 00 00 00 00 02 19 05
15 01 00 00 00 00 02 1B 00
15 01 00 00 00 00 02 21 03
15 01 00 00 00 00 02 22 02
15 01 00 00 00 00 02 23 02
15 01 00 00 00 00 02 24 02
15 01 00 00 00 00 02 25 04
15 01 00 00 00 00 02 29 10
15 01 00 00 00 00 02 2B DC
15 01 00 00 00 00 02 2D 1F
15 01 00 00 00 00 02 2F FC
15 01 00 00 00 00 02 30 22
15 01 00 00 00 00 02 33 F8
15 01 00 00 00 00 02 34 E0
15 01 00 00 00 00 02 35 00
15 01 00 00 00 00 02 3B F9
15 01 00 00 00 00 02 3D FF
15 01 00 00 00 00 02 45 00
15 01 00 00 00 00 02 46 FF
15 01 00 00 00 00 02 55 00
15 01 00 00 00 00 02 56 FC
15 01 00 00 00 00 02 5E FE
15 01 00 00 00 00 02 5F FF
15 01 00 00 00 00 02 60 02
15 01 00 00 00 00 02 65 FA
15 01 00 00 00 00 02 66 FF
15 01 00 00 00 00 02 67 FF
15 01 00 00 00 00 02 6E 00
15 01 00 00 00 00 02 6F 00
15 01 00 00 00 00 02 70 00
15 01 00 00 00 00 02 71 01
/*avdd 7.9v*/
15 01 00 00 00 00 02 FE 9B
15 01 00 00 00 00 02 0B 4E
		/* init code */
		15 01 00 00 00 00 02 FE 00
		15 01 00 00 00 00 02 C2 08
		15 01 00 00 00 00 02 35 00
		15 01 00 00 00 00 02 53 20
		39 01 00 00 00 00 03 51 00 00
		05 01 00 00 64 00 01 11
		05 01 00 00 14 00 01 29
		];
		qcom,mdss-dsi-on-command-state = "dsi_lp_mode";
		qcom,mdss-dsi-timing-switch-command = [
39 00 00 40 00 00 02 FE 00
39 00 00 40 00 00 02 2F 05
39 00 00 40 00 00 02 FE 5A
39 00 00 40 00 00 02 47 FF
39 00 00 40 00 00 02 48 F0
39 00 00 40 00 00 02 49 3A
39 00 00 40 00 00 02 4A 00
39 00 00 40 00 00 02 4B 10
39 00 00 40 00 00 02 4C FC
39 00 00 40 00 00 02 4F 22
39 00 00 40 00 00 02 50 30
39 00 00 40 00 00 02 51 00
39 00 00 40 00 00 02 53 08
39 00 00 40 00 00 02 58 05
39 00 00 40 00 00 02 59 00
39 00 00 40 00 00 02 60 00
39 00 00 40 00 00 02 61 00
39 00 00 40 00 00 02 68 F6
39 00 00 40 00 00 02 69 00
39 00 00 40 00 00 02 70 00
39 00 00 40 00 00 02 79 01
39 00 00 40 00 00 02 7A 00
39 00 00 40 00 00 02 7F 02
39 00 00 40 00 00 02 80 01
39 00 00 40 00 00 02 88 00
39 00 00 40 00 00 02 89 00
39 00 00 40 00 00 02 8A 00
39 00 00 40 00 00 02 8C FF
39 00 00 40 00 00 02 90 00
39 00 00 40 00 00 02 91 30
39 00 00 40 00 00 02 92 10
39 00 00 40 00 00 02 93 10
39 00 00 40 00 00 02 94 09
39 00 00 40 00 00 02 95 1D
39 00 00 40 00 00 02 98 0E
39 00 00 40 00 00 02 99 16
39 00 00 40 00 00 02 9A 10
39 00 00 40 00 00 02 A0 10
39 00 00 40 00 00 02 A2 09
39 00 00 40 00 00 02 A3 06
39 00 00 40 00 00 02 AA 00
39 00 00 40 00 00 02 AB 00
39 00 00 40 00 00 02 B2 07
39 00 00 40 00 00 02 B3 03
39 00 00 40 00 00 02 BA 01
39 00 00 40 00 00 02 BB 01
39 00 00 40 00 00 02 BC 02
39 00 00 40 00 00 02 BD 00
39 00 00 40 00 00 02 C2 04
39 00 00 40 00 00 02 C3 04
39 00 00 40 00 00 02 C4 02
39 00 00 40 00 00 02 C9 05
39 00 00 40 00 00 02 CA 01
39 00 00 40 00 00 02 CB 01
39 00 00 40 00 00 02 DA 70
39 00 00 40 00 00 02 DB 4C
39 00 00 40 00 00 02 DC 3F
39 00 00 40 00 00 02 DD 15
39 00 00 40 00 00 02 DE 12
39 00 00 40 00 00 02 DF 1B
39 00 00 40 00 00 02 E2 23
39 00 00 40 00 00 02 E3 3C
39 00 00 40 00 00 02 E4 28
39 00 00 40 00 00 02 EA 1F
39 00 00 40 00 00 02 EB 1A
39 00 00 40 00 00 02 EC 14
39 00 00 40 00 00 02 F3 10
39 00 00 40 00 00 02 F4 08
39 00 00 40 00 00 02 FE 5B
39 00 00 40 00 00 02 01 12
39 00 00 40 00 00 02 02 0B
39 00 00 40 00 00 02 03 04
39 00 00 40 00 00 02 09 08
39 00 00 40 00 00 02 0A 05
39 00 00 40 00 00 02 11 08
39 00 00 40 00 00 02 12 05
39 00 00 40 00 00 02 18 0A
39 00 00 40 00 00 02 19 05
39 00 00 40 00 00 02 1B 00
39 00 00 40 00 00 02 21 03
39 00 00 40 00 00 02 22 02
39 00 00 40 00 00 02 23 02
39 00 00 40 00 00 02 24 02
39 00 00 40 00 00 02 25 04
39 00 00 40 00 00 02 29 10
39 00 00 40 00 00 02 2B DC
39 00 00 40 00 00 02 2D 1F
39 00 00 40 00 00 02 2F FC
39 00 00 40 00 00 02 30 22
39 00 00 40 00 00 02 33 F8
39 00 00 40 00 00 02 34 E0
39 00 00 40 00 00 02 35 00
39 00 00 40 00 00 02 3B F9
39 00 00 40 00 00 02 3D FF
39 00 00 40 00 00 02 45 00
39 00 00 40 00 00 02 46 FF
39 00 00 40 00 00 02 55 00
39 00 00 40 00 00 02 56 FC
39 00 00 40 00 00 02 5E FE
39 00 00 40 00 00 02 5F FF
39 00 00 40 00 00 02 60 02
39 00 00 40 00 00 02 65 FA
39 00 00 40 00 00 02 66 FF
39 00 00 40 00 00 02 67 FF
39 00 00 40 00 00 02 6E 00
39 00 00 40 00 00 02 6F 00
39 00 00 40 00 00 02 70 00
39 00 00 40 00 00 02 71 01
		39 00 00 00 00 00 02 FE 00
		];
		qcom,mdss-dsi-timing-switch-command-state =
		"dsi_lp_mode";
/* DPHY regular margins */
qcom,mdss-dsi-panel-phy-timings = [00 23 09 09 1A 18
	09 09 09 02 04 00 1D 0E];
	};
	timing@3{
		cell-index = <3>;
		qcom,mdss-dsi-panel-width = <1216>;
		qcom,mdss-dsi-panel-height = <2688>;
		qcom,mdss-dsi-h-front-porch = <8>;
		qcom,mdss-dsi-h-back-porch = <12>;
		qcom,mdss-dsi-h-pulse-width = <8>;
		qcom,mdss-dsi-h-sync-skew = <0>;
		qcom,mdss-dsi-v-back-porch = <8>;
		qcom,mdss-dsi-v-front-porch = <56>;
		qcom,mdss-dsi-v-pulse-width = <8>;
		qcom,mdss-dsi-h-sync-pulse = <0>;
		qcom,mdss-dsi-h-left-border = <0>;
		qcom,mdss-dsi-h-right-border = <0>;
		qcom,mdss-dsi-v-top-border = <0>;
		qcom,mdss-dsi-v-bottom-border = <0>;
		qcom,mdss-dsi-panel-framerate = <144>;
		qcom,mdss-mdp-transfer-time-us = <6235>;
		/*qcom,mdss-dsi-panel-clockrate = <1060474224>;*/
		/*qcom,mdss-dsi-panel-clockrate = <1052220000>; 144HZ*/
        #include "dsi-panel-zte-bf375-rm692h5-6p8-common.dtsi"

		qcom,mdss-dsi-on-command = [
		/* ESD RECOVER */
		15 01 00 00 00 00 02 FE D4
		15 01 00 00 00 00 02 40 03
		15 01 00 00 00 00 02 FE FD
		15 01 00 00 00 00 02 80 06
		15 01 00 00 00 00 02 83 00
		15 01 00 00 00 00 02 EE 00
		15 01 00 00 00 00 02 EF 00
		15 01 00 00 00 00 02 FE D0
		15 01 00 00 00 00 02 7E 80
		15 01 00 00 00 00 02 FE B6
		15 01 00 00 00 00 02 01 74
		15 01 00 00 00 00 02 FE A1
		15 01 00 00 00 00 02 74 72
		15 01 00 00 00 00 02 C3 C3
		15 01 00 00 00 00 02 C4 FF
		15 01 00 00 00 00 02 C5 7F
		/*10bit 3.75 begin*/
		15 01 00 00 00 00 02 FE 00
		15 01 00 00 00 00 02 FA 01
		15 01 00 00 00 00 02 FE D2
		15 01 00 00 00 00 02 97 08
		15 01 00 00 00 00 02 36 11
		15 01 00 00 00 00 02 39 ab
		15 01 00 00 00 00 02 3A 30
		15 01 00 00 00 00 02 3B 80
		15 01 00 00 00 00 02 3D 0a
		15 01 00 00 00 00 02 3F 80
		15 01 00 00 00 00 02 40 04
		15 01 00 00 00 00 02 41 c0
		15 01 00 00 00 00 02 42 00
		15 01 00 00 00 00 02 43 10
		15 01 00 00 00 00 02 44 02
		15 01 00 00 00 00 02 45 60
		15 01 00 00 00 00 02 46 02
		15 01 00 00 00 00 02 47 60
		15 01 00 00 00 00 02 48 02
		15 01 00 00 00 00 02 49 00
		15 01 00 00 00 00 02 4A 02
		15 01 00 00 00 00 02 4B 31
		15 01 00 00 00 00 02 4D 20
		15 01 00 00 00 00 02 4E 01
		15 01 00 00 00 00 02 4F 68
		15 01 00 00 00 00 02 50 00
		15 01 00 00 00 00 02 51 08
		15 01 00 00 00 00 02 53 0c
		15 01 00 00 00 00 02 54 06
		15 01 00 00 00 00 02 55 67
		15 01 00 00 00 00 02 56 05
		15 01 00 00 00 00 02 58 ad
		15 01 00 00 00 00 02 59 18
		15 01 00 00 00 00 02 5A 00
		15 01 00 00 00 00 02 5B 11
		15 01 00 00 00 00 02 5C 00
		15 01 00 00 00 00 02 5D 07
		15 01 00 00 00 00 02 5E 10
		15 01 00 00 00 00 02 5F 20
		15 01 00 00 00 00 02 60 00
		15 01 00 00 00 00 02 61 06
		15 01 00 00 00 00 02 62 0f
		15 01 00 00 00 00 02 63 0f
		15 01 00 00 00 00 02 64 33
		15 01 00 00 00 00 02 65 0e
		15 01 00 00 00 00 02 66 1c
		15 01 00 00 00 00 02 67 2a
		15 01 00 00 00 00 02 68 38
		15 01 00 00 00 00 02 69 46
		15 01 00 00 00 00 02 6A 54
		15 01 00 00 00 00 02 6B 62
		15 01 00 00 00 00 02 6C 69
		15 01 00 00 00 00 02 6D 70
		15 01 00 00 00 00 02 6E 77
		15 01 00 00 00 00 02 6F 79
		15 01 00 00 00 00 02 70 7b
		15 01 00 00 00 00 02 71 7d
		15 01 00 00 00 00 02 72 7e
		15 01 00 00 00 00 02 73 02
		15 01 00 00 00 00 02 74 02
		15 01 00 00 00 00 02 75 22
		15 01 00 00 00 00 02 76 00
		15 01 00 00 00 00 02 77 2a
		15 01 00 00 00 00 02 78 40
		15 01 00 00 00 00 02 79 2a
		15 01 00 00 00 00 02 7A be
		15 01 00 00 00 00 02 7B 3a
		15 01 00 00 00 00 02 7C fc
		15 01 00 00 00 00 02 7D 3a
		15 01 00 00 00 00 02 7E fa
		15 01 00 00 00 00 02 7F 3a
		15 01 00 00 00 00 02 80 f8
		15 01 00 00 00 00 02 81 3b
		15 01 00 00 00 00 02 82 38
		15 01 00 00 00 00 02 83 3b
		15 01 00 00 00 00 02 84 78
		15 01 00 00 00 00 02 85 3b
		15 01 00 00 00 00 02 86 b6
		15 01 00 00 00 00 02 87 4b
		15 01 00 00 00 00 02 88 f6
		15 01 00 00 00 00 02 89 4c
		15 01 00 00 00 00 02 8A 34
		15 01 00 00 00 00 02 8B 4c
		15 01 00 00 00 00 02 8C 74
		15 01 00 00 00 00 02 8D 5c
		15 01 00 00 00 00 02 8E 74
		15 01 00 00 00 00 02 8F 8c
		15 01 00 00 00 00 02 90 f4
		15 01 00 00 00 00 02 91 00
		15 01 00 00 00 00 02 92 00
		15 01 00 00 00 00 02 93 00
		15 01 00 00 00 00 02 94 00
		15 01 00 00 00 00 02 95 00
		15 01 00 00 00 00 02 96 00
		/*10bit 3.75 end*/
		/*acl function*/
		15 01 00 00 00 00 02 FE 34
		15 01 00 00 00 00 02 82 C0
		15 01 00 00 00 00 02 83 04
		15 01 00 00 00 00 02 00 08
		15 01 00 00 00 00 02 1C 00
		15 01 00 00 00 00 02 1D 10
		15 01 00 00 00 00 02 49 05
		15 01 00 00 00 00 02 1E 00
		15 01 00 00 00 00 02 1F 00
		15 01 00 00 00 00 02 20 00
		15 01 00 00 00 00 02 21 70
		15 01 00 00 00 00 02 22 00
		15 01 00 00 00 00 02 23 F8
		15 01 00 00 00 00 02 24 77
		15 01 00 00 00 00 02 25 F8
		15 01 00 00 00 00 02 26 F8
		15 01 00 00 00 00 02 2F 00
		15 01 00 00 00 00 02 30 00
		15 01 00 00 00 00 02 31 00
		15 01 00 00 00 00 02 32 00
		15 01 00 00 00 00 02 33 00
		15 01 00 00 00 00 02 34 00
		15 01 00 00 00 00 02 35 00
		15 01 00 00 00 00 02 36 C4
		15 01 00 00 00 00 02 37 00
		15 01 00 00 00 00 02 38 87
		15 01 00 00 00 00 02 39 00
		15 01 00 00 00 00 02 3A 4B
		15 01 00 00 00 00 02 3B 00
		15 01 00 00 00 00 02 3D 00
		15 01 00 00 00 00 02 3F 00
		15 01 00 00 00 00 02 40 00
		15 01 00 00 00 00 02 41 00
		15 01 00 00 00 00 02 42 00
		15 01 00 00 00 00 02 54 03
		15 01 00 00 00 00 02 55 77
		15 01 00 00 00 00 02 56 F8
		15 01 00 00 00 00 02 58 F8
		15 01 00 00 00 00 02 59 77
		15 01 00 00 00 00 02 5A F8
		15 01 00 00 00 00 02 5B F8
		15 01 00 00 00 00 02 5C 77
		15 01 00 00 00 00 02 5D F8
		15 01 00 00 00 00 02 5E F8
		15 01 00 00 00 00 02 5F 77
		15 01 00 00 00 00 02 60 F8
		15 01 00 00 00 00 02 61 F8
		15 01 00 00 00 00 02 62 77
		15 01 00 00 00 00 02 63 F8
		15 01 00 00 00 00 02 64 F8
		15 01 00 00 00 00 02 65 77
		15 01 00 00 00 00 02 66 F8
		15 01 00 00 00 00 02 67 F8
		15 01 00 00 00 00 02 77 07
		15 01 00 00 00 00 02 78 F8
/*FDC effect*/
15 01 00 00 00 00 02 FE 00
15 01 00 00 00 00 02 2F 00
15 01 00 00 00 00 02 FE 5A
15 01 00 00 00 00 02 47 FF
15 01 00 00 00 00 02 48 F0
15 01 00 00 00 00 02 49 3A
15 01 00 00 00 00 02 4A 00
15 01 00 00 00 00 02 4B 10
15 01 00 00 00 00 02 4C FC
15 01 00 00 00 00 02 4F 22
15 01 00 00 00 00 02 50 30
15 01 00 00 00 00 02 51 00
15 01 00 00 00 00 02 53 06
15 01 00 00 00 00 02 58 05
15 01 00 00 00 00 02 59 00
15 01 00 00 00 00 02 60 00
15 01 00 00 00 00 02 61 00
15 01 00 00 00 00 02 68 F6
15 01 00 00 00 00 02 69 00
15 01 00 00 00 00 02 70 00
15 01 00 00 00 00 02 79 01
15 01 00 00 00 00 02 7A 00
15 01 00 00 00 00 02 7F 02
15 01 00 00 00 00 02 80 01
15 01 00 00 00 00 02 88 00
15 01 00 00 00 00 02 89 00
15 01 00 00 00 00 02 8A 00
15 01 00 00 00 00 02 8C FF
15 01 00 00 00 00 02 90 00
15 01 00 00 00 00 02 91 30
15 01 00 00 00 00 02 92 10
15 01 00 00 00 00 02 93 10
15 01 00 00 00 00 02 94 09
15 01 00 00 00 00 02 95 1D
15 01 00 00 00 00 02 98 0E
15 01 00 00 00 00 02 99 20
15 01 00 00 00 00 02 9A 10
15 01 00 00 00 00 02 A0 10
15 01 00 00 00 00 02 A2 09
15 01 00 00 00 00 02 A3 06
15 01 00 00 00 00 02 AA 00
15 01 00 00 00 00 02 AB 02
15 01 00 00 00 00 02 B2 07
15 01 00 00 00 00 02 B3 02
15 01 00 00 00 00 02 BA 01
15 01 00 00 00 00 02 BB 01
15 01 00 00 00 00 02 BC 02
15 01 00 00 00 00 02 BD 00
15 01 00 00 00 00 02 C2 04
15 01 00 00 00 00 02 C3 04
15 01 00 00 00 00 02 C4 02
15 01 00 00 00 00 02 C9 05
15 01 00 00 00 00 02 CA 01
15 01 00 00 00 00 02 CB 01
15 01 00 00 00 00 02 DA 70
15 01 00 00 00 00 02 DB 4C
15 01 00 00 00 00 02 DC 38
15 01 00 00 00 00 02 DD 15
15 01 00 00 00 00 02 DE 12
15 01 00 00 00 00 02 DF 1B
15 01 00 00 00 00 02 E2 23
15 01 00 00 00 00 02 E3 3C
15 01 00 00 00 00 02 E4 28
15 01 00 00 00 00 02 EA 1F
15 01 00 00 00 00 02 EB 1A
15 01 00 00 00 00 02 EC 14
15 01 00 00 00 00 02 F3 10
15 01 00 00 00 00 02 F4 0D
15 01 00 00 00 00 02 FE 5B
15 01 00 00 00 00 02 01 12
15 01 00 00 00 00 02 02 0B
15 01 00 00 00 00 02 03 04
15 01 00 00 00 00 02 09 08
15 01 00 00 00 00 02 0A 05
15 01 00 00 00 00 02 11 08
15 01 00 00 00 00 02 12 05
15 01 00 00 00 00 02 18 0A
15 01 00 00 00 00 02 19 05
15 01 00 00 00 00 02 1B 00
15 01 00 00 00 00 02 21 03
15 01 00 00 00 00 02 22 02
15 01 00 00 00 00 02 23 02
15 01 00 00 00 00 02 24 02
15 01 00 00 00 00 02 25 04
15 01 00 00 00 00 02 29 10
15 01 00 00 00 00 02 2A FF
15 01 00 00 00 00 02 2B DC
15 01 00 00 00 00 02 2D 1F
15 01 00 00 00 00 02 2F FC
15 01 00 00 00 00 02 30 22
15 01 00 00 00 00 02 33 F8
15 01 00 00 00 00 02 34 E0
15 01 00 00 00 00 02 35 00
15 01 00 00 00 00 02 37 06
15 01 00 00 00 00 02 3B F9
15 01 00 00 00 00 02 3D ff
15 01 00 00 00 00 02 45 00
15 01 00 00 00 00 02 46 FF
15 01 00 00 00 00 02 55 00
15 01 00 00 00 00 02 56 00
15 01 00 00 00 00 02 5E FE
15 01 00 00 00 00 02 5F ff
15 01 00 00 00 00 02 60 02
15 01 00 00 00 00 02 65 FA
15 01 00 00 00 00 02 66 FF
15 01 00 00 00 00 02 67 FF
15 01 00 00 00 00 02 6E 00
15 01 00 00 00 00 02 6F 00
15 01 00 00 00 00 02 70 00
15 01 00 00 00 00 02 71 01
/*avdd 7.9v*/
15 01 00 00 00 00 02 FE 9B
15 01 00 00 00 00 02 0B 4E
		/*init code*/
		15 01 00 00 00 00 02 FE 00
		15 01 00 00 00 00 02 C2 08
		15 01 00 00 00 00 02 35 00
		15 01 00 00 00 00 02 53 20
		39 01 00 00 00 00 03 51 00 00
		05 01 00 00 64 00 01 11
		05 01 00 00 14 00 01 29
		];
		qcom,mdss-dsi-on-command-state = "dsi_lp_mode";
		qcom,mdss-dsi-timing-switch-command = [
39 00 00 40 00 00 02 FE 00
39 00 00 40 00 00 02 2F 00
39 00 00 40 00 00 02 FE 5A
39 00 00 40 00 00 02 47 FF
39 00 00 40 00 00 02 48 F0
39 00 00 40 00 00 02 49 3A
39 00 00 40 00 00 02 4A 00
39 00 00 40 00 00 02 4B 10
39 00 00 40 00 00 02 4C FC
39 00 00 40 00 00 02 4F 22
39 00 00 40 00 00 02 50 30
39 00 00 40 00 00 02 51 00
39 00 00 40 00 00 02 53 06
39 00 00 40 00 00 02 58 05
39 00 00 40 00 00 02 59 00
39 00 00 40 00 00 02 60 00
39 00 00 40 00 00 02 61 00
39 00 00 40 00 00 02 68 F6
39 00 00 40 00 00 02 69 00
39 00 00 40 00 00 02 70 00
39 00 00 40 00 00 02 79 01
39 00 00 40 00 00 02 7A 00
39 00 00 40 00 00 02 7F 02
39 00 00 40 00 00 02 80 01
39 00 00 40 00 00 02 88 00
39 00 00 40 00 00 02 89 00
39 00 00 40 00 00 02 8A 00
39 00 00 40 00 00 02 8C FF
39 00 00 40 00 00 02 90 00
39 00 00 40 00 00 02 91 30
39 00 00 40 00 00 02 92 10
39 00 00 40 00 00 02 93 10
39 00 00 40 00 00 02 94 09
39 00 00 40 00 00 02 95 1D
39 00 00 40 00 00 02 98 0E
39 00 00 40 00 00 02 99 20
39 00 00 40 00 00 02 9A 10
39 00 00 40 00 00 02 A0 10
39 00 00 40 00 00 02 A2 09
39 00 00 40 00 00 02 A3 06
39 00 00 40 00 00 02 AA 00
39 00 00 40 00 00 02 AB 02
39 00 00 40 00 00 02 B2 07
39 00 00 40 00 00 02 B3 02
39 00 00 40 00 00 02 BA 01
39 00 00 40 00 00 02 BB 01
39 00 00 40 00 00 02 BC 02
39 00 00 40 00 00 02 BD 00
39 00 00 40 00 00 02 C2 04
39 00 00 40 00 00 02 C3 04
39 00 00 40 00 00 02 C4 02
39 00 00 40 00 00 02 C9 05
39 00 00 40 00 00 02 CA 01
39 00 00 40 00 00 02 CB 01
39 00 00 40 00 00 02 DA 70
39 00 00 40 00 00 02 DB 4C
39 00 00 40 00 00 02 DC 38
39 00 00 40 00 00 02 DD 15
39 00 00 40 00 00 02 DE 12
39 00 00 40 00 00 02 DF 1B
39 00 00 40 00 00 02 E2 23
39 00 00 40 00 00 02 E3 3C
39 00 00 40 00 00 02 E4 28
39 00 00 40 00 00 02 EA 1F
39 00 00 40 00 00 02 EB 1A
39 00 00 40 00 00 02 EC 14
39 00 00 40 00 00 02 F3 10
39 00 00 40 00 00 02 F4 0D
39 00 00 40 00 00 02 FE 5B
39 00 00 40 00 00 02 01 12
39 00 00 40 00 00 02 02 0B
39 00 00 40 00 00 02 03 04
39 00 00 40 00 00 02 09 08
39 00 00 40 00 00 02 0A 05
39 00 00 40 00 00 02 11 08
39 00 00 40 00 00 02 12 05
39 00 00 40 00 00 02 18 0A
39 00 00 40 00 00 02 19 05
39 00 00 40 00 00 02 1B 00
39 00 00 40 00 00 02 21 03
39 00 00 40 00 00 02 22 02
39 00 00 40 00 00 02 23 02
39 00 00 40 00 00 02 24 02
39 00 00 40 00 00 02 25 04
39 00 00 40 00 00 02 29 10
39 00 00 40 00 00 02 2A FF
39 00 00 40 00 00 02 2B DC
39 00 00 40 00 00 02 2D 1F
39 00 00 40 00 00 02 2F FC
39 00 00 40 00 00 02 30 22
39 00 00 40 00 00 02 33 F8
39 00 00 40 00 00 02 34 E0
39 00 00 40 00 00 02 35 00
39 00 00 40 00 00 02 37 06
39 00 00 40 00 00 02 3B F9
39 00 00 40 00 00 02 3D ff
39 00 00 40 00 00 02 45 00
39 00 00 40 00 00 02 46 FF
39 00 00 40 00 00 02 55 00
39 00 00 40 00 00 02 56 00
39 00 00 40 00 00 02 5E FE
39 00 00 40 00 00 02 5F ff
39 00 00 40 00 00 02 60 02
39 00 00 40 00 00 02 65 FA
39 00 00 40 00 00 02 66 FF
39 00 00 40 00 00 02 67 FF
39 00 00 40 00 00 02 6E 00
39 00 00 40 00 00 02 6F 00
39 00 00 40 00 00 02 70 00
39 00 00 40 00 00 02 71 01
		39 00 00 00 00 00 02 FE 00
		];
		qcom,mdss-dsi-timing-switch-command-state =
		"dsi_lp_mode";
/* DPHY regular margins */
qcom,mdss-dsi-panel-phy-timings = [00 23 09 09 1A 18
	09 09 09 02 04 00 1D 0E];
	};
};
